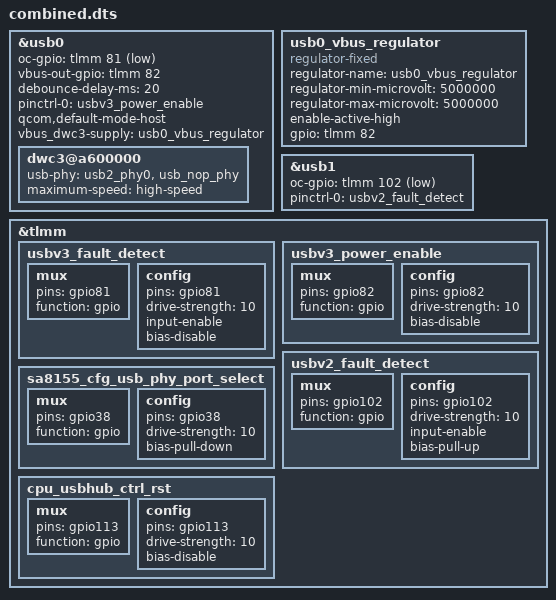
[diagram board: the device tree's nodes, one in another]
/*
 * USB DTS - CCS20 (unconfirmed style) - everything in one place, for review.
 * Generated by tools/tool/usb_dts_tool.py. Every NEEDS REVIEW comment and the report's review tables are
 * open decisions - nothing marked so is verified.
 *
 * WHERE EACH PART BELONGS in the real tree (this file is a view, not a drop-in file):
 *   1. controller blocks  -> overlay .dts, top level
 *   2. TLMM pinctrl nodes -> pinmux .dtsi inside &tlmm (only safely generated TLMM states appear in --out;
 *                           unsupported controller pins are listed in the report, not emitted here) -
 *                           split below into without-hub / with-hub (see "HUB" in the Gen5 Signal
 *                           Name or Interface Group - these are the pins that belong to a separate,
 *                           I2C-attached hub IC, not the USB controller itself)
 *   3. regulators         -> INSIDE a parent node of the overlay, NOT top level
 */

/* 1. USB CONTROLLER BLOCKS */

/* pattern unconfirmed - BOTH possible shapes are previewed below (section 1-preview), from the same real GPIO/polarity data. Neither is confirmed; pick one and re-run with --pattern to get it written into --out. */

/* 1-PREVIEW. BOTH possible consumer-wiring shapes, for comparison - NEITHER is
 * confirmed or written to --out. Pick one (ask whoever owns this project's BSP/base
 * devicetree which one it actually expects) and re-run with --pattern to confirm it. */

/* usb0 (USB30) - IF controller style: */
&usb0 {
	oc-gpio = <&tlmm 81 GPIO_ACTIVE_LOW>;
	vbus-out-gpio = <&tlmm 82 GPIO_ACTIVE_HIGH>;
	debounce-delay-ms = <20>;
	pinctrl-names = "default";
	pinctrl-0 = <&usbv3_fault_detect &usbv3_power_enable>;

	qcom,default-mode-host;

	dwc3@a600000 {
		usb-phy = <&usb2_phy0>, <&usb_nop_phy>;
		maximum-speed = "high-speed";
	};
};

/* usb0 (USB30) - IF regulator style: */
usb0_vbus_regulator: usb0_vbus_regulator {
	compatible = "regulator-fixed";
	regulator-name = "usb0_vbus_regulator";
	regulator-min-microvolt = <5000000>;
	regulator-max-microvolt = <5000000>;
	enable-active-high;
	gpio = <&tlmm 82 GPIO_ACTIVE_HIGH>;
};

&usb0 {
	status = "okay";
	vbus_dwc3-supply = <&usb0_vbus_regulator>;
	pinctrl-names = "default";
	pinctrl-0 = <&usbv3_power_enable>;
	qcom,default-mode-host;
};

/* over-current (GPIO_81, GPIO_ACTIVE_LOW) has no confirmed wiring under the regulator pattern in this codebase - not previewed */

/* usb1 (USB20) - IF controller style: */
&usb1 {
	oc-gpio = <&tlmm 102 GPIO_ACTIVE_LOW>;
	pinctrl-names = "default";
	pinctrl-0 = <&usbv2_fault_detect>;

	/* NEEDS REVIEW: debounce-delay-ms, qcom,default-mode-host, the dwc3 child (unit address, usb-phy, maximum-speed) - only confirmed for the reference instance;
	 * add from a real reference if this instance needs them. */
};

/* usb1 (USB20) - IF regulator style: */
/* no vbus pin found for this instance */

/* 2. USB PINCTRL (existing nodes as updated, plus any new ones) */

/* 2a. Without hub (pure USB controller) */

&tlmm {
	usbv3_fault_detect: usbv3_fault_detect {
		mux {
			pins = "gpio81";
			function = "gpio";
		};
		config {
			pins = "gpio81";
			drive-strength = <10>;
			input-enable;
			bias-disable;
		};
	};

	usbv3_power_enable: usbv3_power_enable {
		mux {
			pins = "gpio82";
			function = "gpio";
		};
		config {
			pins = "gpio82";
			drive-strength = <10>;
			/* NEEDS REVIEW: output pin - add output-high or output-low per hardware design (level is not derivable from Excel) */
			bias-disable;
		};
	};

	usbv2_fault_detect: usbv2_fault_detect {
		mux {
			pins = "gpio102";
			function = "gpio";
		};
		config {
			pins = "gpio102";
			drive-strength = <10>;
			input-enable;
			bias-pull-up;
		};
	};

	sa8155_cfg_usb_phy_port_select: sa8155_cfg_usb_phy_port_select {
		mux {
			pins = "gpio38";
			function = "gpio";
		};
		config {
			pins = "gpio38";
			drive-strength = <10>;
			/* NEEDS REVIEW: output pin - add output-high or output-low per hardware design (level is not derivable from Excel) */
			bias-pull-down;
		};
	};
};

/* 2b. With hub (I2C-attached hub IC) */

&tlmm {
	cpu_usbhub_ctrl_rst: cpu_usbhub_ctrl_rst {
		mux {
			pins = "gpio113";
			function = "gpio";
		};
		config {
			pins = "gpio113";
			drive-strength = <10>;
			/* NEEDS REVIEW: output pin - add output-high or output-low per hardware design (level is not derivable from Excel) */
			bias-disable;
		};
	};
};
